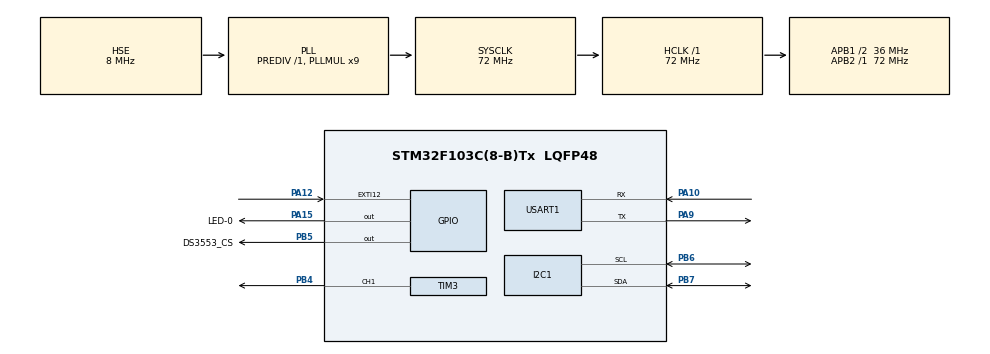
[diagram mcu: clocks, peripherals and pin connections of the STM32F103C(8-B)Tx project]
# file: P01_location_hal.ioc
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I2C1.I2C_Mode=I2C_Standard
Mcu.Family=STM32F1
Mcu.Name=STM32F103C(8-B)Tx
Mcu.Package=LQFP48
NVIC.PriorityGroup=NVIC_PRIORITYGROUP_4
PA10.Mode=Asynchronous
PA10.Signal=USART1_RX
PA12.GPIO_ModeDefaultEXTI=GPIO_MODE_IT_FALLING
PA12.GPIO_PuPd=GPIO_PULLUP
PA12.Signal=GPXTI12
PA13.Mode=Serial_Wire
PA13.Signal=SYS_JTMS-SWDIO
PA14.Mode=Serial_Wire
PA14.Signal=SYS_JTCK-SWCLK
PA15.GPIO_Label=LED-0
PA15.GPIO_Speed=GPIO_SPEED_FREQ_HIGH
PA15.Signal=GPIO_Output
PA9.Mode=Asynchronous
PA9.Signal=USART1_TX
PB4.Signal=S_TIM3_CH1
PB5.GPIO_Label=DS3553_CS
PB5.GPIO_Speed=GPIO_SPEED_FREQ_HIGH
PB5.PinState=GPIO_PIN_SET
PB5.Signal=GPIO_Output
PB6.Mode=I2C
PB6.Signal=I2C1_SCL
PB7.Mode=I2C
PB7.Signal=I2C1_SDA
PC14-OSC32_IN.Mode=LSE-External-Oscillator
PC14-OSC32_IN.Signal=RCC_OSC32_IN
PC15-OSC32_OUT.Mode=LSE-External-Oscillator
PC15-OSC32_OUT.Signal=RCC_OSC32_OUT
PD0-OSC_IN.Mode=HSE-External-Oscillator
PD0-OSC_IN.Signal=RCC_OSC_IN
PD1-OSC_OUT.Mode=HSE-External-Oscillator
PD1-OSC_OUT.Signal=RCC_OSC_OUT
ProjectManager.HeapSize=0x200
ProjectManager.StackSize=0x400
ProjectManager.TargetToolchain=MDK-ARM V5.32
RCC.ADCPresc=RCC_ADCPCLK2_DIV6
RCC.AHBFreq_Value=72000000
RCC.APB1CLKDivider=RCC_HCLK_DIV2
RCC.APB1Freq_Value=36000000
RCC.APB1TimFreq_Value=72000000
RCC.APB2Freq_Value=72000000
RCC.APB2TimFreq_Value=72000000
RCC.HCLKFreq_Value=72000000
RCC.PLLMUL=RCC_PLL_MUL9
RCC.PLLSourceVirtual=RCC_PLLSOURCE_HSE
RCC.SYSCLKFreq_VALUE=72000000
RCC.SYSCLKSource=RCC_SYSCLKSOURCE_PLLCLK
RCC.USBFreq_Value=72000000
SH.S_TIM3_CH1.0=TIM3_CH1,PWM Generation1 CH1
TIM3.Channel-PWM\ Generation1\ CH1=TIM_CHANNEL_1
TIM3.Period=20-1
TIM3.Prescaler=7200-1
TIM3.Pulse-PWM\ Generation1\ CH1=10
USART1.VirtualMode=VM_ASYNC
VP_TIM3_VS_ClockSourceINT.Mode=Internal
board=custom

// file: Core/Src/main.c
/* USER CODE BEGIN Header */
/**
 ******************************************************************************
 * @file           : main.c
 * @brief          : Main program body
 ******************************************************************************
 * @attention
 *
 * Copyright (c) 2025 STMicroelectronics.
 * All rights reserved.
 *
 * This software is licensed under terms that can be found in the LICENSE file
 * in the root directory of this software component.
 * If no LICENSE file comes with this software, it is provided AS-IS.
 *
 ******************************************************************************
 */
/* USER CODE END Header */
#include "main.h"
#include "i2c.h"
#include "tim.h"
#include "usart.h"
#include "gpio.h"

/* USER CODE BEGIN Includes */
#include "Com_debug.h"
#include "Int_led.h"
#include "Int_buzzer.h"
#include "Int_step.h"
/* USER CODE END Includes */

void SystemClock_Config(void);

int main(void)
{

  /* MCU Configuration--------------------------------------------------------*/

  /* Reset of all peripherals, Initializes the Flash interface and the Systick. */
  HAL_Init();

  /* Configure the system clock */
  SystemClock_Config();

  /* Initialize all configured peripherals */
  MX_GPIO_Init();
  MX_USART1_UART_Init();
  MX_TIM3_Init();
  MX_I2C1_Init();
  /* USER CODE BEGIN 2 */

  // 使用串口输出  => 打印一次hello world需要多长时间  =>  1ms时间  根据波特率115200bit/s
  // HAL_UART_Transmit(&huart1, "Hello World", 11, 1000);
  // printf("hello world");
  debug_printf("hello world %d", 10);

  // 测试全彩灯
  // Int_led_send_data(0);

  // 测试全彩灯 闪烁
  // for (uint8_t i = 0; i < 10; i++)
  // {
  //   Int_led_blink(LED_RED, 300);
  // }

  // 测试全彩灯 彩虹灯效果
  // for (uint8_t i = 0; i < 5; i++)
  // {
  //   // ms * 88 是一轮的时间
  //   Int_led_rainbow(20);
  // }

  // 测试蜂鸣器
  // Int_buzzer_on();
  // HAL_Delay(2000);
  // Int_buzzer_off();
  // Int_buzzer_music();

  // 测试i2c连接DS3553芯片
  Int_step_init();

  /* USER CODE END 2 */

  /* Infinite loop */
  /* USER CODE BEGIN WHILE */
  while (1)
  {
    uint32_t count = Int_step_get_count();
    debug_printf("count: %d", count);
    HAL_Delay(1000);
    /* USER CODE END WHILE */

  }
}

void SystemClock_Config(void)
{
  RCC_OscInitTypeDef RCC_OscInitStruct = {0};
  RCC_ClkInitTypeDef RCC_ClkInitStruct = {0};

  /** Initializes the RCC Oscillators according to the specified parameters
  * in the RCC_OscInitTypeDef structure.
  */
  RCC_OscInitStruct.OscillatorType = RCC_OSCILLATORTYPE_HSE;
  RCC_OscInitStruct.HSEState = RCC_HSE_ON;
  RCC_OscInitStruct.HSEPredivValue = RCC_HSE_PREDIV_DIV1;
  RCC_OscInitStruct.HSIState = RCC_HSI_ON;
  RCC_OscInitStruct.PLL.PLLState = RCC_PLL_ON;
  RCC_OscInitStruct.PLL.PLLSource = RCC_PLLSOURCE_HSE;
  RCC_OscInitStruct.PLL.PLLMUL = RCC_PLL_MUL9;
  if (HAL_RCC_OscConfig(&RCC_OscInitStruct) != HAL_OK)
  {
    Error_Handler();
  }

  /** Initializes the CPU, AHB and APB buses clocks
  */
  RCC_ClkInitStruct.ClockType = RCC_CLOCKTYPE_HCLK|RCC_CLOCKTYPE_SYSCLK
                              |RCC_CLOCKTYPE_PCLK1|RCC_CLOCKTYPE_PCLK2;
  RCC_ClkInitStruct.SYSCLKSource = RCC_SYSCLKSOURCE_PLLCLK;
  RCC_ClkInitStruct.AHBCLKDivider = RCC_SYSCLK_DIV1;
  RCC_ClkInitStruct.APB1CLKDivider = RCC_HCLK_DIV2;
  RCC_ClkInitStruct.APB2CLKDivider = RCC_HCLK_DIV1;

  if (HAL_RCC_ClockConfig(&RCC_ClkInitStruct, FLASH_LATENCY_2) != HAL_OK)
  {
    Error_Handler();
  }
}

void Error_Handler(void)
{
  __disable_irq();
  while (1)
  {
  }
}
